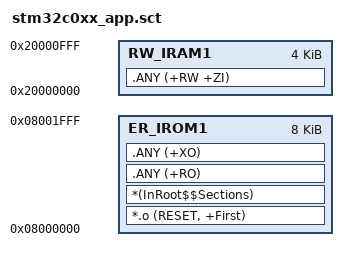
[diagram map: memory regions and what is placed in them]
#! armclang --target=arm-arm-none-eabi -march=armv8-m.main -E -xc

; *************************************************************
; *** Scatter-Loading Description File generated by uVision ***
; *************************************************************

#define CODE_START 0x08000000
#define APP_CODE_SIZE 0x2000

#define DATA_START 0x20000000
#define DATA_SIZE 0x1000


LR_IROM1 CODE_START APP_CODE_SIZE  {    ; load region size_region
  ER_IROM1 CODE_START APP_CODE_SIZE  {  ; load address = execution address
   *.o (RESET, +First)
   *(InRoot$$Sections)
   .ANY (+RO)
   .ANY (+XO)
  }
  RW_IRAM1 DATA_START DATA_SIZE  {  ; RW data
   .ANY (+RW +ZI)
  }
}
